# cslr_pllc register map
Vendor: Texas Instruments
Peripheral module from a debugger description file.
Registers are 32-bit, access per field, reset 0x0 unless marked. A register's access mark holds for its fields unless they carry their own. Offsets are as the file gives them; lines under a group give offsets from that group; [hi:lo] are bit positions; {n}, {i} and the like mark numbered series; 'fields as' and 'values as' point back to an identical list; <NAME> marks a mode.

## PLLC — This module propagates clocks to the device.
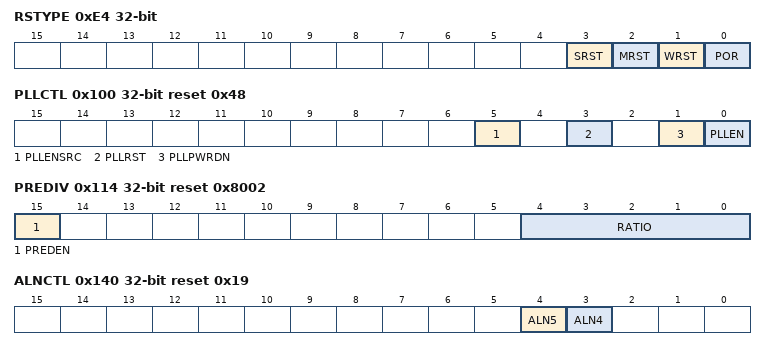
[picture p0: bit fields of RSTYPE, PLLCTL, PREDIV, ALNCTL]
0xE4 RSTYPE ro — Latches the cause of the last reset.
  [3] SRST — System reset.
    0=NO (System reset was not the last reset to occur.); 1=YES (System reset was the last reset to occur.)
  [2] MRST — Max reset.
    0=NO (Max reset was not the last reset to occur.); 1=YES (Max reset was the last reset to occur.)
  [1] WRST — Warm reset.
    0=NO (Warm reset was not the last reset to occur.); 1=YES (Warm reset was the last reset to occur.)
  [0] POR — Power-on reset.
    0=NO (Power-on reset was not the last reset to occur.); 1=YES (Power-on reset was the last reset to occur.)
0x100 PLLCTL reset 0x48 — Controls PLL operations.
  [5] PLLENSRC rw — PLL enable source bit.
    0=REGBIT (PLLEN bit is enabled. The value of the PLLEN bit will affect the operation of the PLL controller.); 1=NONREGBIT (PLLEN bit is disabled. The value of the PLLEN bit has no effect on the operation of the PLL controller.)
  [3] PLLRST rw — PLL reset bit.
    0=NO (PLL reset is released.); 1=YES (PLL reset is asserted.)
  [1] PLLPWRDN rw — PLL power-down mode select bit.
    0=NO (PLL is operational.); 1=YES (PLL is placed in power-down state, i.e. all analog circuitry in the PLL is turned-off.)
  [0] PLLEN rw — PLL enable bit.
    0=BYPASS (Bypass mode. Divider PREDIV and PLL are bypassed. All the system clocks (SYSCLKn) are divided down directly from the input reference clock.); 1=PLL (PLL mode. Divider PREDIV and PLL are not bypassed. PLL output path is enabled. All the system clocks (SYCLKn) are divided down from PLL output.)
0x110 PLLM — Defines the multiply factor for the clock output of the pre-divider.
  [5:0] PLLM rw — PLL multiplier bits. Defines the frequency multiplier of the input reference clock in conjunction with the PLL divider ratio bits (RATIO) in the PREDIV register.
0x114 PREDIV reset 0x8002 — Defines the input reference clock divider.
  [15] PREDEN rw — Pre-divider enable bit.
    0=DISABLE (Pre-divider is disabled. No clock output.); 1=ENABLE (Pre-divider is enabled.)
  [4:0] RATIO rw — Divider ratio bits.
0x138 PLLCMD — Contains the command bit for the GO operation.
  [0] GOSET rw — GO operation command for SYSCLK rate change and phase alignment. Before setting this bit to 1 to initiate a GO operation, check the GOSTAT bit in the PLLSTAT register to ensure all previous GO operations have completed.
    0=CLRBIT (No effect. Write of 0 clears bit to 0.); 1=SET (Initiates GO operation. Write of 1 initiates GO operation. Once set, GOSET remains set but further writes of 1 can initiate the GO operation.)
0x13C PLLSTAT ro — Shows the PLL controller status.
  [0] GOSTAT — GO operation status.
    0=NONE (Go operation is not in progress. SYSCLK divide ratios are not being changed.); 1=INPROG (GO operation is in progress. SYSCLK divide ratios are being changed.)
0x140 ALNCTL ro reset 0x19 — Indicates if clock should be aligned during GO operation. This register should not be modified.
  [4] ALN5 — SYSCLK5 alignment. Do not change the default values of these fields.
    0=NO (Do not align SYSCLK5 to other SYSCLKs during GO operation. If SYS5 in DCHANGE is set to 1, SYSCLK5 switches to the new ratio immediately after the GOSET bit in PLLCMD is set.); 1=YES (Align SYSCLK5 when the GOSET bit in PLLCMD is set. The SYSCLK5 ratio is set to the ratio programmed in the RATIO bit in PLLDIV5.)
  [3] ALN4 — SYSCLK4 alignment. Do not change the default values of these fields.
    0=NO (Do not align SYSCLK4 to other SYSCLKs during GO operation. If SYS4 in DCHANGE is set to 1, SYSCLK4 switches to the new ratio immediately after the GOSET bit in PLLCMD is set.); 1=YES (Align SYSCLK4 when the GOSET bit in PLLCMD is set. The SYSCLK4 ratio is set to the ratio programmed in the RATIO bit in PLLDIV4.)
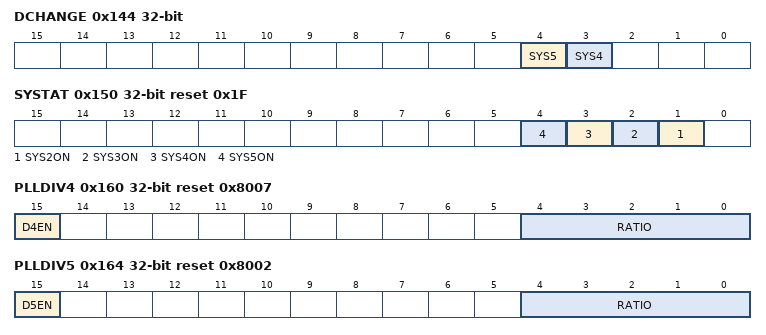
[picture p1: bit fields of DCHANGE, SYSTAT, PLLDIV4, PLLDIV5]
0x144 DCHANGE ro — Indicates if SYSCLK divide ratio has been modified.
  [4] SYS5 — Identifies when the SYSCLK5 divide ratio has been modified.
    0=NO (SYSCLK5 ratio has not been modified. When GOSET is set, SYSCLK5 will not be affected.); 1=YES (SYSCLK5 ratio has been modified. When GOSET is set, SYSCLK5 will change to the new ratio.)
  [3] SYS4 — Identifies when the SYSCLK4 divide ratio has been modified.
    0=NO (SYSCLK4 ratio has not been modified. When GOSET is set, SYSCLK4 will not be affected.); 1=YES (SYSCLK4 ratio has been modified. When GOSET is set, SYSCLK4 will change to the new ratio.)
0x150 SYSTAT ro reset 0x1F — Indicates SYSCLK on/off status.
  [n-1] SYS{n}ON (n=2..5) — SYSCLK{n} on status.
    0=OFF (SYSCLK{n} is gated.); 1=ON (SYSCLK{n} is on.)
0x160 PLLDIV4 reset 0x8007 — Divider control register for divider D4.
  [15] D4EN rw — Divider D4 enable bit.
    0=DISABLE (Divider D4 is disabled. No clock output.); 1=ENABLE (Divider D4 is enabled.)
  [4:0] RATIO rw — Divider ratio bits.
0x164 PLLDIV5 reset 0x8002 — Divider control register for divider D5.
  [15] D5EN rw — Divider D5 enable bit.
    0=DISABLE (Divider D5 is disabled. No clock output.); 1=ENABLE (Divider D5 is enabled.)
  [4:0] RATIO rw — Divider ratio bits.
